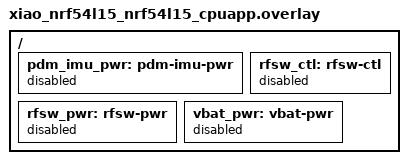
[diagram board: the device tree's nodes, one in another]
/*
 * MCUboot DTS overlay for XIAO nRF54L15 Sense
 *
 * Disable board-specific fixed regulators that MCUboot does not need
 * and that cause initialization failures in the minimal MCUboot context.
 */

/ {
	pdm_imu_pwr: pdm-imu-pwr {
		status = "disabled";
	};
	rfsw_ctl: rfsw-ctl {
		status = "disabled";
	};
	rfsw_pwr: rfsw-pwr {
		status = "disabled";
	};
	vbat_pwr: vbat-pwr {
		status = "disabled";
	};
};
